# dm648_cslr_vic_001 register map
Vendor: Texas Instruments
Peripheral module from a debugger description file.
Registers are 32-bit, access not given, reset 0x0 unless marked. A register's access mark holds for its fields unless they carry their own. Offsets are as the file gives them; lines under a group give offsets from that group; [hi:lo] are bit positions; {n}, {i} and the like mark numbered series; 'fields as' and 'values as' point back to an identical list; <NAME> marks a mode.

## VIC — The VIC port provides single-bit interpolated VCXO control with resolution from 9 bits to up to 16 bits.
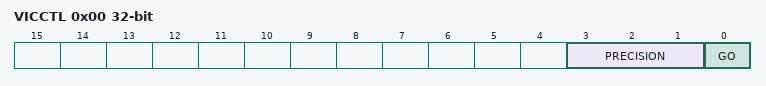
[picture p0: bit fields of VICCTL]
0x00 VICCTL — VIC Control Register
  [3:1] PRECISION rw — Precision bits determine the resolution of the interpolation. The PRECISION bits can only be written when the GO bit is cleared to 0. If the GO bit is set to 1, a write to the PRECISION bits does not change the bits.
    0=16BITS; 1=15BITS; 2=14BITS; 3=13BITS; 4=12BITS; 5=11BITS; 6=10BITS; 7=9BITS
  [0] GO rw — The GO bit can be written to at any time.
0x04 VICIN — VIC Input Register
  [15:0] VICINBITS rw — The DSP writes the input bits for VCXO interpolated control to the VIC input bits.
0x08 VICDIV — VIC Clock Divider Register
  [15:0] VICCLKDIV rw — The VIC clock divider bits define the clock divider for the VIC interpolation frequency.
